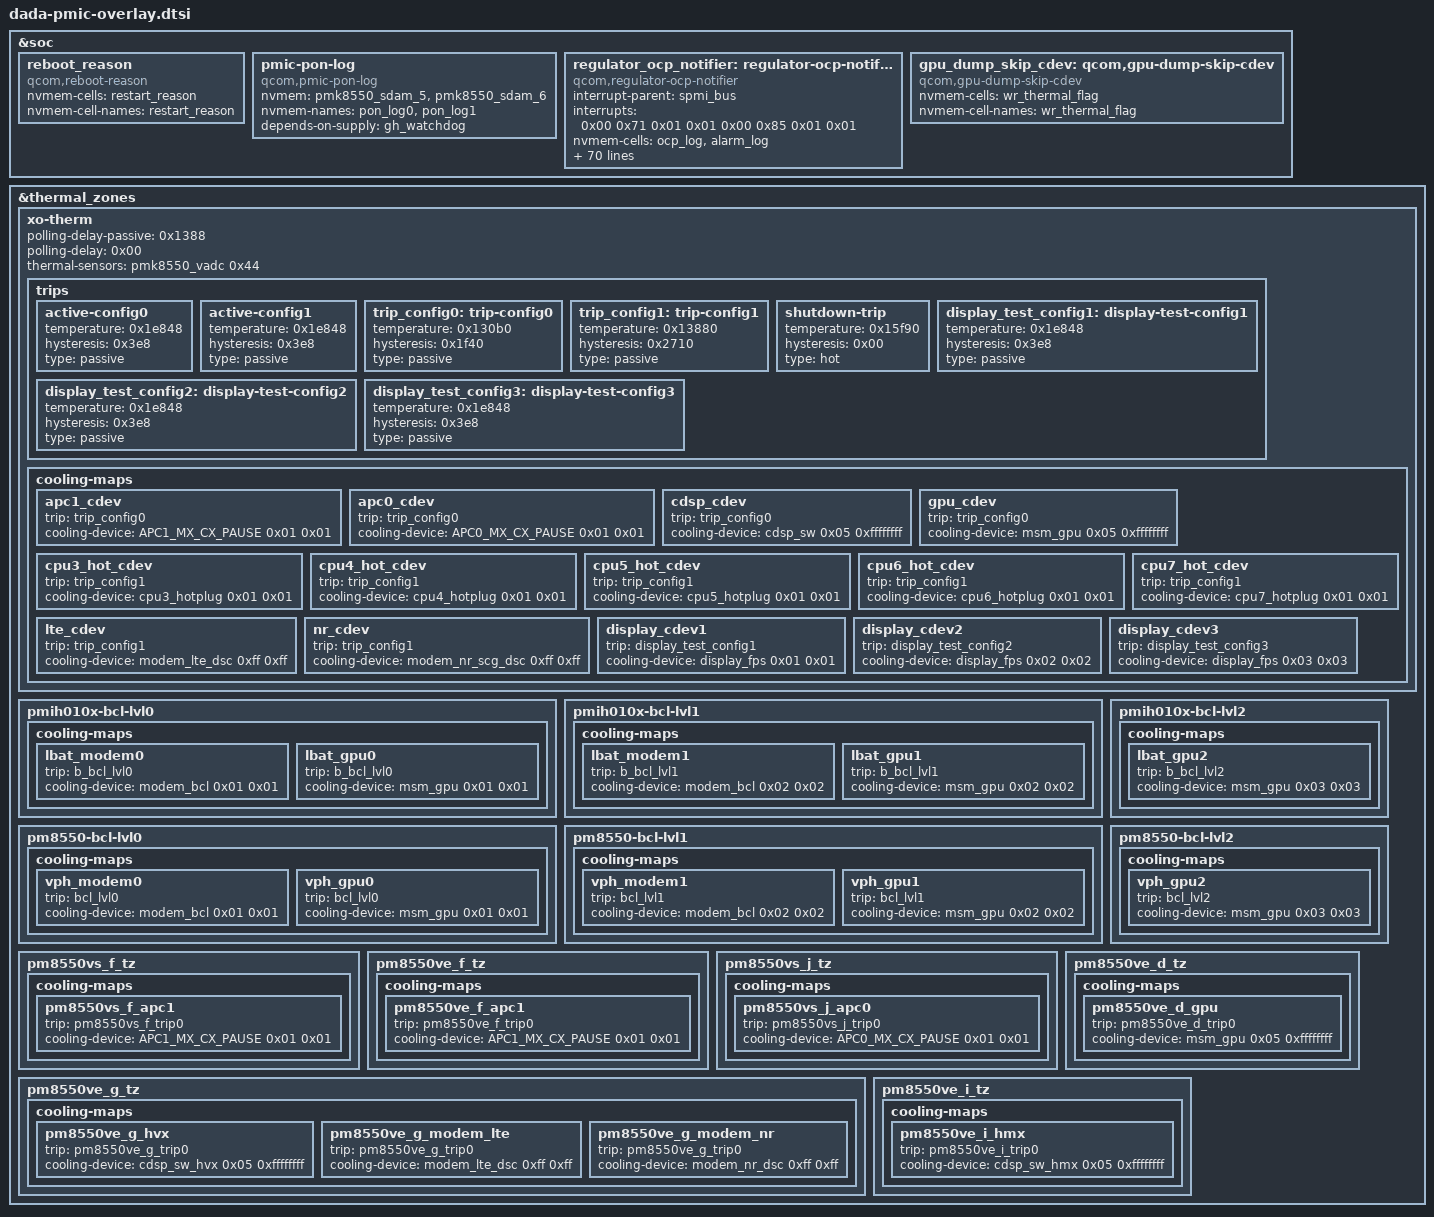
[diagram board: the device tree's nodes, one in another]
// SPDX-License-Identifier: BSD-3-Clause
/*
 * Copyright (c) 2023-2024 Qualcomm Innovation Center, Inc. All rights reserved.
 * Copyright (c) 2025 The LineageOS Project
 */

#include "dada-pm8010.dtsi"
#include "dada-pm8550.dtsi"
#include "dada-pm8550ve.dtsi"
#include "dada-pm8550vs.dtsi"
#include "dada-pmd802x.dtsi"
#include "dada-pmih010x.dtsi"
#include "dada-pmk8550.dtsi"
#include "dada-pmr735d.dtsi"

&soc {
	reboot_reason {
		compatible = "qcom,reboot-reason";
		nvmem-cells = <&restart_reason>;
		nvmem-cell-names = "restart_reason";
	};

	pmic-pon-log {
		compatible = "qcom,pmic-pon-log";
		nvmem = <&pmk8550_sdam_5 &pmk8550_sdam_6>;
		nvmem-names = "pon_log0", "pon_log1";
		depends-on-supply = <&gh_watchdog>;
	};

	regulator_ocp_notifier: regulator-ocp-notifier {
		compatible = "qcom,regulator-ocp-notifier";
		interrupt-parent = <&spmi_bus>;
		interrupts = <0x00 0x71 0x01 0x01 0x00 0x85 0x01 0x01>;
		nvmem-cells = <&ocp_log &alarm_log>;
		nvmem-cell-names = "ocp_log", "alarm_log";
		periph-1c1-supply = <&L1B>;
		periph-1c2-supply = <&L2B>;
		periph-1c4-supply = <&L4B>;
		periph-1c5-supply = <&L5B>;
		periph-1c6-supply = <&L6B>;
		periph-1c7-supply = <&L7B>;
		periph-1c8-supply = <&L8B>;
		periph-1c9-supply = <&L9B>;
		periph-1ca-supply = <&L10B>;
		periph-1cb-supply = <&L11B>;
		periph-1cc-supply = <&L12B>;
		periph-1cd-supply = <&L13B>;
		periph-1ce-supply = <&L14B>;
		periph-1cf-supply = <&L15B>;
		periph-1d0-supply = <&L16B>;
		periph-1d1-supply = <&L17B>;
		periph-1e4-supply = <&BOB1>;
		periph-1e6-supply = <&BOB2>;
		periph-39b-supply = <&S1D>;
		periph-39e-supply = <&S2D_LEVEL>;
		periph-3a1-supply = <&S3D>;
		periph-3a4-supply = <&S4D>;
		periph-3a7-supply = <&S5D_LEVEL>;
		periph-3c1-supply = <&L1D>;
		periph-3c2-supply = <&L2D>;
		periph-3c3-supply = <&L3D>;
		periph-5c1-supply = <&L1F>;
		periph-5c2-supply = <&L2F>;
		periph-5c3-supply = <&L3F>;
		periph-69b-supply = <&S1G>;
		periph-69e-supply = <&S2G_LEVEL>;
		periph-6a1-supply = <&S3G>;
		periph-6a4-supply = <&S4G>;
		periph-6a7-supply = <&S5G_LEVEL>;
		periph-6ad-supply = <&S7G_LEVEL>;
		periph-6c1-supply = <&L1G>;
		periph-6c2-supply = <&L2G>;
		periph-6c3-supply = <&L3G>;
		periph-89b-supply = <&S1I_LEVEL>;
		periph-8a1-supply = <&S3I_LEVEL>;
		periph-8a7-supply = <&S5I_LEVEL>;
		periph-8aa-supply = <&S6I_LEVEL>;
		periph-8ad-supply = <&S7I>;
		periph-8b0-supply = <&S8I>;
		periph-8c1-supply = <&L1I>;
		periph-8c2-supply = <&L2I>;
		periph-8c3-supply = <&L3I>;
		periph-99b-supply = <&S1J_LEVEL>;
		periph-99e-supply = <&S2J>;
		periph-9a1-supply = <&S3J>;
		periph-9c1-supply = <&L1J>;
		periph-9c2-supply = <&L2J>;
		periph-9c3-supply = <&L3J_LEVEL>;
		periph-ac1-supply = <&L1K>;
		periph-ac2-supply = <&L2K>;
		periph-ac3-supply = <&L3K>;
		periph-ac4-supply = <&L4K>;
		periph-ac5-supply = <&L5K>;
		periph-ac6-supply = <&L6K>;
		periph-ac7-supply = <&L7K>;
		periph-c40-supply = <&L1M>;
		periph-c41-supply = <&L2M>;
		periph-c42-supply = <&L3M>;
		periph-c43-supply = <&L4M>;
		periph-c44-supply = <&L5M>;
		periph-c45-supply = <&L6M>;
		periph-c46-supply = <&L7M>;
		periph-5a7-supply = <&S5F>;
		periph-5b0-supply = <&S8F_LEVEL>;
	};
};

&thermal_zones {
	xo-therm {
		polling-delay-passive = <0x1388>;
		polling-delay = <0x00>;
		thermal-sensors = <&pmk8550_vadc 0x44>;

		trips {

			active-config0 {
				temperature = <0x1e848>;
				hysteresis = <0x3e8>;
				type = "passive";
			};

			active-config1 {
				temperature = <0x1e848>;
				hysteresis = <0x3e8>;
				type = "passive";
			};

			trip_config0: trip-config0 {
				temperature = <0x130b0>;
				hysteresis = <0x1f40>;
				type = "passive";
			};

			trip_config1: trip-config1 {
				temperature = <0x13880>;
				hysteresis = <0x2710>;
				type = "passive";
			};

			shutdown-trip {
				temperature = <0x15f90>;
				hysteresis = <0x00>;
				type = "hot";
			};

			display_test_config1: display-test-config1 {
				temperature = <0x1e848>;
				hysteresis = <0x3e8>;
				type = "passive";
			};

			display_test_config2: display-test-config2 {
				temperature = <0x1e848>;
				hysteresis = <0x3e8>;
				type = "passive";
			};

			display_test_config3: display-test-config3 {
				temperature = <0x1e848>;
				hysteresis = <0x3e8>;
				type = "passive";
			};
		};
	};
};

&soc {
	gpu_dump_skip_cdev: qcom,gpu-dump-skip-cdev {
		compatible = "qcom,gpu-dump-skip-cdev";
		nvmem-cells = <&wr_thermal_flag>;
		nvmem-cell-names = "wr_thermal_flag";
		#cooling-cells = <0x02>;
	};
};

&thermal_zones {
	pmih010x-bcl-lvl0 {

		cooling-maps {

			lbat_modem0 {
				trip = <&b_bcl_lvl0>;
				cooling-device = <&modem_bcl 0x01 0x01>;
			};

			lbat_gpu0 {
				trip = <&b_bcl_lvl0>;
				cooling-device = <&msm_gpu 0x01 0x01>;
			};
		};
	};

	pmih010x-bcl-lvl1 {

		cooling-maps {

			lbat_modem1 {
				trip = <&b_bcl_lvl1>;
				cooling-device = <&modem_bcl 0x02 0x02>;
			};

			lbat_gpu1 {
				trip = <&b_bcl_lvl1>;
				cooling-device = <&msm_gpu 0x02 0x02>;
			};
		};
	};

	pmih010x-bcl-lvl2 {

		cooling-maps {

			lbat_gpu2 {
				trip = <&b_bcl_lvl2>;
				cooling-device = <&msm_gpu 0x03 0x03>;
			};
		};
	};

	pm8550-bcl-lvl0 {

		cooling-maps {

			vph_modem0 {
				trip = <&bcl_lvl0>;
				cooling-device = <&modem_bcl 0x01 0x01>;
			};

			vph_gpu0 {
				trip = <&bcl_lvl0>;
				cooling-device = <&msm_gpu 0x01 0x01>;
			};
		};
	};

	pm8550-bcl-lvl1 {

		cooling-maps {

			vph_modem1 {
				trip = <&bcl_lvl1>;
				cooling-device = <&modem_bcl 0x02 0x02>;
			};

			vph_gpu1 {
				trip = <&bcl_lvl1>;
				cooling-device = <&msm_gpu 0x02 0x02>;
			};
		};
	};

	pm8550-bcl-lvl2 {

		cooling-maps {

			vph_gpu2 {
				trip = <&bcl_lvl2>;
				cooling-device = <&msm_gpu 0x03 0x03>;
			};
		};
	};

	pm8550vs_f_tz {

		cooling-maps {

			pm8550vs_f_apc1 {
				trip = <&pm8550vs_f_trip0>;
				cooling-device = <&APC1_MX_CX_PAUSE 0x01 0x01>;
			};
		};
	};

	pm8550ve_f_tz {

		cooling-maps {

			pm8550ve_f_apc1 {
				trip = <&pm8550ve_f_trip0>;
				cooling-device = <&APC1_MX_CX_PAUSE 0x01 0x01>;
			};
		};
	};

	pm8550vs_j_tz {

		cooling-maps {

			pm8550vs_j_apc0 {
				trip = <&pm8550vs_j_trip0>;
				cooling-device = <&APC0_MX_CX_PAUSE 0x01 0x01>;
			};
		};
	};

	pm8550ve_d_tz {

		cooling-maps {

			pm8550ve_d_gpu {
				trip = <&pm8550ve_d_trip0>;
				cooling-device = <&msm_gpu 0x05 0xffffffff>;
			};
		};
	};

	pm8550ve_g_tz {

		cooling-maps {

			pm8550ve_g_hvx {
				trip = <&pm8550ve_g_trip0>;
				cooling-device = <&cdsp_sw_hvx 0x05 0xffffffff>;
			};

			pm8550ve_g_modem_lte {
				trip = <&pm8550ve_g_trip0>;
				cooling-device = <&modem_lte_dsc 0xff 0xff>;
			};

			pm8550ve_g_modem_nr {
				trip = <&pm8550ve_g_trip0>;
				cooling-device = <&modem_nr_dsc 0xff 0xff>;
			};
		};
	};

	pm8550ve_i_tz {

		cooling-maps {

			pm8550ve_i_hmx {
				trip = <&pm8550ve_i_trip0>;
				cooling-device = <&cdsp_sw_hmx 0x05 0xffffffff>;
			};
		};
	};

	xo-therm {

		cooling-maps {

			apc1_cdev {
				trip = <&trip_config0>;
				cooling-device = <&APC1_MX_CX_PAUSE 0x01 0x01>;
			};

			apc0_cdev {
				trip = <&trip_config0>;
				cooling-device = <&APC0_MX_CX_PAUSE 0x01 0x01>;
			};

			cdsp_cdev {
				trip = <&trip_config0>;
				cooling-device = <&cdsp_sw 0x05 0xffffffff>;
			};

			gpu_cdev {
				trip = <&trip_config0>;
				cooling-device = <&msm_gpu 0x05 0xffffffff>;
			};

			cpu3_hot_cdev {
				trip = <&trip_config1>;
				cooling-device = <&cpu3_hotplug 0x01 0x01>;
			};

			cpu4_hot_cdev {
				trip = <&trip_config1>;
				cooling-device = <&cpu4_hotplug 0x01 0x01>;
			};

			cpu5_hot_cdev {
				trip = <&trip_config1>;
				cooling-device = <&cpu5_hotplug 0x01 0x01>;
			};

			cpu6_hot_cdev {
				trip = <&trip_config1>;
				cooling-device = <&cpu6_hotplug 0x01 0x01>;
			};

			cpu7_hot_cdev {
				trip = <&trip_config1>;
				cooling-device = <&cpu7_hotplug 0x01 0x01>;
			};

			lte_cdev {
				trip = <&trip_config1>;
				cooling-device = <&modem_lte_dsc 0xff 0xff>;
			};

			nr_cdev {
				trip = <&trip_config1>;
				cooling-device = <&modem_nr_scg_dsc 0xff 0xff>;
			};

			display_cdev1 {
				trip = <&display_test_config1>;
				cooling-device = <&display_fps 0x01 0x01>;
			};

			display_cdev2 {
				trip = <&display_test_config2>;
				cooling-device = <&display_fps 0x02 0x02>;
			};

			display_cdev3 {
				trip = <&display_test_config3>;
				cooling-device = <&display_fps 0x03 0x03>;
			};
		};
	};
};
